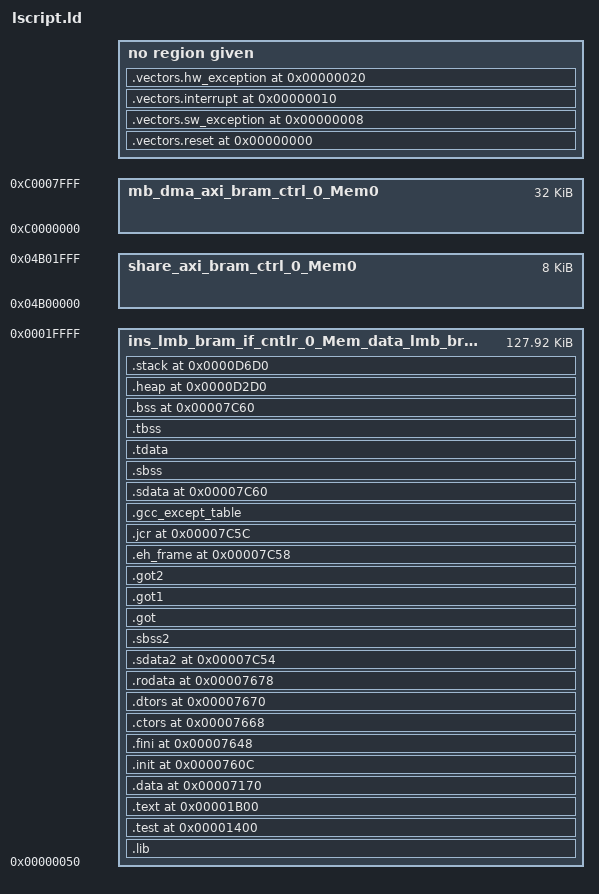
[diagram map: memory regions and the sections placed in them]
/*******************************************************************/
/*                                                                 */
/* This file is automatically generated by linker script generator.*/
/*                                                                 */
/* Version:                                 */
/*                                                                 */
/* Copyright (c) 2010-2016 Xilinx, Inc.  All rights reserved.      */
/*                                                                 */
/* Description : MicroBlaze Linker Script                          */
/*                                                                 */
/*******************************************************************/

_STACK_SIZE = DEFINED(_STACK_SIZE) ? _STACK_SIZE : 0x400;
_HEAP_SIZE = DEFINED(_HEAP_SIZE) ? _HEAP_SIZE : 0x400;


/* Define Memories in the system */

MEMORY
{
   ins_lmb_bram_if_cntlr_0_Mem_data_lmb_bram_if_cntlr_1_Mem : ORIGIN = 0x50, LENGTH = 0x1FFB0
   share_axi_bram_ctrl_0_Mem0 : ORIGIN = 0x4B00000, LENGTH = 0x2000
   mb_dma_axi_bram_ctrl_0_Mem0 : ORIGIN = 0xC0000000, LENGTH = 0x8000
}

/* Specify the default entry point to the program */

ENTRY(_start)

/* Define the sections, and where they are mapped in memory */

SECTIONS
{
.vectors.reset 0x0 : {
   KEEP (*(.vectors.reset))
} 

.vectors.sw_exception 0x8 : {
   KEEP (*(.vectors.sw_exception))
} 

.vectors.interrupt 0x10 : {
   KEEP (*(.vectors.interrupt))
} 

.vectors.hw_exception 0x20 : {
   KEEP (*(.vectors.hw_exception))
} 

.lib : {

	libc.a 
	libgcc.a 
	libgloss.a 
	libm.a 
    libxil.a(.text)
	libxil.a(.text.*)
}  > ins_lmb_bram_if_cntlr_0_Mem_data_lmb_bram_if_cntlr_1_Mem

.test 0x1400: {
    *LED.o(.text)
	*LED.o(.text.*)
	*platform.o(.text)
	*platform.o(.text.*)
	*util.o(.text)
	*util.o(.text.*)
} > ins_lmb_bram_if_cntlr_0_Mem_data_lmb_bram_if_cntlr_1_Mem

.text 0x1b00: {
   *(.text)
   *(.text.*) 
   *(.gnu.linkonce.t.*)
} > ins_lmb_bram_if_cntlr_0_Mem_data_lmb_bram_if_cntlr_1_Mem

.data 0x7170: {
   . = ALIGN(4);
   __data_start = .;
   *(.data)
   *(.data.*)
   *(.gnu.linkonce.d.*)
   __data_end = . + 0x4;
} > ins_lmb_bram_if_cntlr_0_Mem_data_lmb_bram_if_cntlr_1_Mem

.init 0x760c: {
   KEEP (*(.init))
} > ins_lmb_bram_if_cntlr_0_Mem_data_lmb_bram_if_cntlr_1_Mem

.fini 0x7648: {
   KEEP (*(.fini))
} > ins_lmb_bram_if_cntlr_0_Mem_data_lmb_bram_if_cntlr_1_Mem

.ctors 0x7668: {
   __CTOR_LIST__ = .;
   ___CTORS_LIST___ = .;
   KEEP (*crtbegin.o(.ctors))
   KEEP (*(EXCLUDE_FILE(*crtend.o) .ctors))
   KEEP (*(SORT(.ctors.*)))
   KEEP (*(.ctors))
   __CTOR_END__ = .;
   ___CTORS_END___ = .;
} > ins_lmb_bram_if_cntlr_0_Mem_data_lmb_bram_if_cntlr_1_Mem

.dtors 0x7670: {
   __DTOR_LIST__ = .;
   ___DTORS_LIST___ = .;
   KEEP (*crtbegin.o(.dtors))
   KEEP (*(EXCLUDE_FILE(*crtend.o) .dtors))
   KEEP (*(SORT(.dtors.*)))
   KEEP (*(.dtors))
   PROVIDE(__DTOR_END__ = .);
   PROVIDE(___DTORS_END___ = .);
} > ins_lmb_bram_if_cntlr_0_Mem_data_lmb_bram_if_cntlr_1_Mem

.rodata 0x7678: {
   __rodata_start = .;
   *(.rodata)
   *(.rodata.*)
   *(.gnu.linkonce.r.*)
   __rodata_end = 0x7c54;
} > ins_lmb_bram_if_cntlr_0_Mem_data_lmb_bram_if_cntlr_1_Mem

.sdata2 0x7C54: {
   . = ALIGN(8);
   __sdata2_start = .;
   *(.sdata2)
   *(.sdata2.*)
   *(.gnu.linkonce.s2.*)
   . = ALIGN(8);
   __sdata2_end = .;
} > ins_lmb_bram_if_cntlr_0_Mem_data_lmb_bram_if_cntlr_1_Mem

.sbss2 : {
   __sbss2_start = .;
   *(.sbss2)
   *(.sbss2.*)
   *(.gnu.linkonce.sb2.*)
   __sbss2_end = .;
} > ins_lmb_bram_if_cntlr_0_Mem_data_lmb_bram_if_cntlr_1_Mem


.got : {
   *(.got)
} > ins_lmb_bram_if_cntlr_0_Mem_data_lmb_bram_if_cntlr_1_Mem

.got1 : {
   *(.got1)
} > ins_lmb_bram_if_cntlr_0_Mem_data_lmb_bram_if_cntlr_1_Mem

.got2 : {
   *(.got2)
} > ins_lmb_bram_if_cntlr_0_Mem_data_lmb_bram_if_cntlr_1_Mem

.eh_frame 0x7C58: {
   *(.eh_frame)
} > ins_lmb_bram_if_cntlr_0_Mem_data_lmb_bram_if_cntlr_1_Mem

.jcr 0x7C5C: {
   *(.jcr)
} > ins_lmb_bram_if_cntlr_0_Mem_data_lmb_bram_if_cntlr_1_Mem

.gcc_except_table : {
   *(.gcc_except_table)
} > ins_lmb_bram_if_cntlr_0_Mem_data_lmb_bram_if_cntlr_1_Mem

.sdata 0x7C60: {
   . = ALIGN(8);
   __sdata_start = .;
   *(.sdata)
   *(.sdata.*)
   *(.gnu.linkonce.s.*)
   __sdata_end = .;
} > ins_lmb_bram_if_cntlr_0_Mem_data_lmb_bram_if_cntlr_1_Mem

.sbss (NOLOAD) : {
   . = ALIGN(4);
   __sbss_start = .;
   *(.sbss)
   *(.sbss.*)
   *(.gnu.linkonce.sb.*)
   . = ALIGN(8);
   __sbss_end = .;
} > ins_lmb_bram_if_cntlr_0_Mem_data_lmb_bram_if_cntlr_1_Mem

.tdata : {
   __tdata_start = .;
   *(.tdata)
   *(.tdata.*)
   *(.gnu.linkonce.td.*)
   __tdata_end = .;
} > ins_lmb_bram_if_cntlr_0_Mem_data_lmb_bram_if_cntlr_1_Mem

.tbss : {
   __tbss_start = .;
   *(.tbss)
   *(.tbss.*)
   *(.gnu.linkonce.tb.*)
   __tbss_end = .;
} > ins_lmb_bram_if_cntlr_0_Mem_data_lmb_bram_if_cntlr_1_Mem

.bss 0x7C60 (NOLOAD) : {
   . = ALIGN(4);
   __bss_start = .;
   *(.bss)
   *(.bss.*)
   *(.gnu.linkonce.b.*)
   *(COMMON)
   . = ALIGN(4);
   __bss_end = . + 0x5588;
} > ins_lmb_bram_if_cntlr_0_Mem_data_lmb_bram_if_cntlr_1_Mem

_SDA_BASE_ = __sdata_start + ((__sbss_end - __sdata_start) / 2 );

_SDA2_BASE_ = __sdata2_start + ((__sbss2_end - __sdata2_start) / 2 );

/* Generate Stack and Heap definitions */


.heap 0xD2D0 (NOLOAD) : {
   . = ALIGN(8);
   _heap = .;
   _heap_start = .;
   . += _HEAP_SIZE;
   _heap_end = .;
} > ins_lmb_bram_if_cntlr_0_Mem_data_lmb_bram_if_cntlr_1_Mem

.stack 0xD6D0 (NOLOAD) : {
   _stack_end = .;
   . += _STACK_SIZE;
   . = ALIGN(8);
   _stack = .;
   __stack = _stack;
} > ins_lmb_bram_if_cntlr_0_Mem_data_lmb_bram_if_cntlr_1_Mem

_end = .;
}
__malloc_top_pad = 0x83e8;
__malloc_current_mallinfo = 0x83f4;
__malloc_max_sbrked_mem = 0x83ec;
__malloc_max_total_mem = 0x83f0;
errno = 0xd2cc;
__errno = 0x7164;
heap_ptr = 0x8420;
__TMC_END__ = 0x760C;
